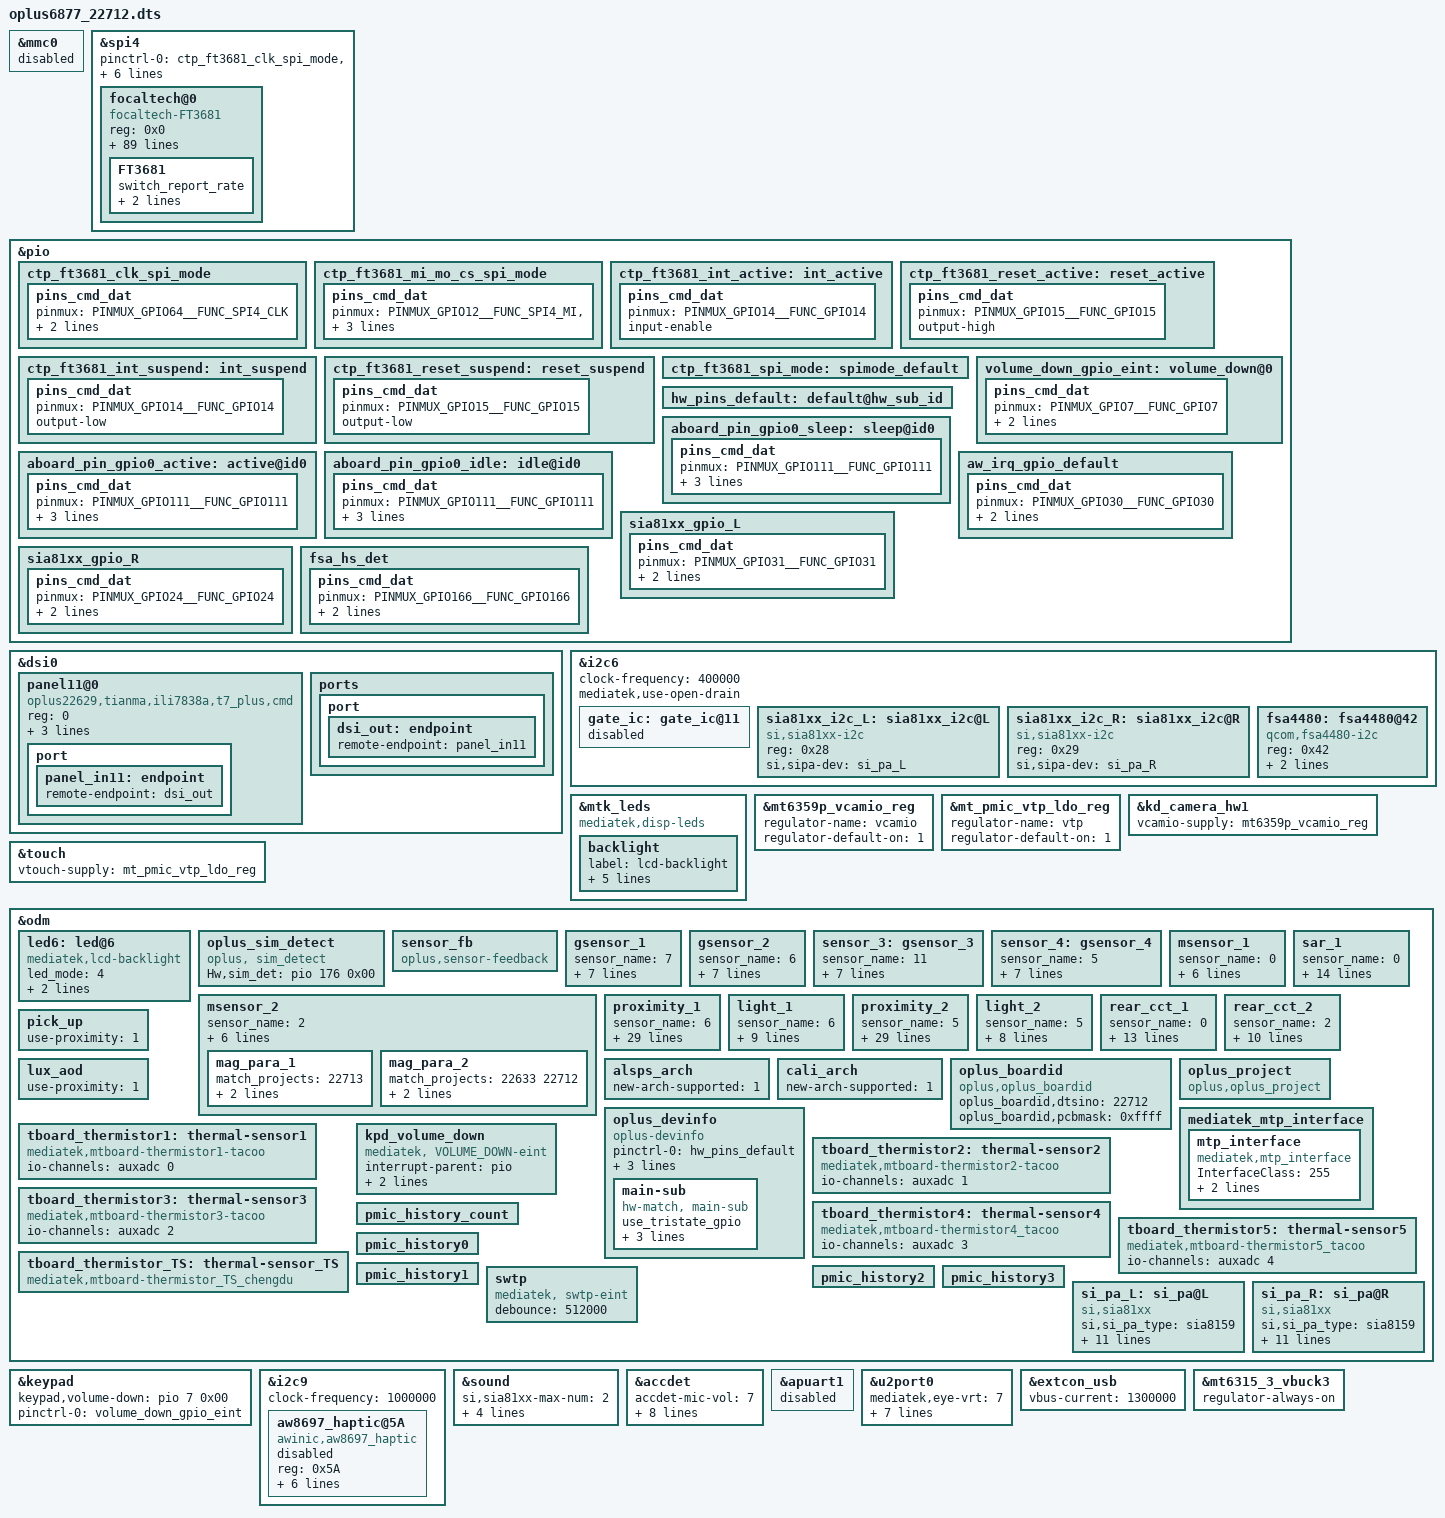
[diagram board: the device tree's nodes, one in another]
/*
 * Mediatek's mt6853 SoC device tree source
 *
 * Copyright (C) 2016 MediaTek Inc.
 *
 * This program is free software; you can redistribute it and/or modify
 * it under the terms of the GNU General Public License version 2 as
 * published by the Free Software Foundation.
 *
 * This program is distributed in the hope that it will be useful,
 * but WITHOUT ANY WARRANTY; without even the implied warranty of
 * MERCHANTABILITY or FITNESS FOR A PARTICULAR PURPOSE.
 * See http://www.gnu.org/licenses/gpl-2.0.html for more details.
 */
/dts-v1/;
/plugin/;
#include "k6877v1_64.dts"
#include "mediatek/nfc/mt6877_chengduB_nfc.dtsi"
/* #ifdef CONFIG_UFF_FINGERPRINT */
#include "mediatek/oplus_uff_22633_22712_22713.dtsi"
/* #endif CONFIG_UFF_FINGERPRINT */

&mmc0 {
        status = "disabled";
};

&spi4 {
	status = "okay";
	#address-cells = <1>;
	#size-cells = <0>;

	pinctrl-names = "default",  "ft3681_int_active",
		"ft3681_reset_active", "ft3681_int_suspend",
		"ft3681_reset_suspend", "ft3681_spi_mode";
	pinctrl-0 = <&ctp_ft3681_clk_spi_mode>, <&ctp_ft3681_mi_mo_cs_spi_mode>;
	pinctrl-1 = <&ctp_ft3681_int_active>;
	pinctrl-2 = <&ctp_ft3681_reset_active>;
	pinctrl-3 = <&ctp_ft3681_int_suspend>;
	pinctrl-4 = <&ctp_ft3681_reset_suspend>;
	pinctrl-5 = <&ctp_ft3681_spi_mode>;

	focaltech@0{
		compatible = "focaltech-FT3681";
		reg = <0x0>;
		chip-name = "FT3681";
		status = "okay";
		spi-max-frequency = <6000000>;
		/* Interrupt && Irq-gpio */
		interrupt-parent = <&pio>;
		interrupts = <14 0x2002>;

		/* Power Config */

		vdd_2v8-supply  = <&mt_pmic_vtp_ldo_reg>;
		vdd_2v8_volt = <3000000>;
		vcc_1v8-supply  = <&mt_pmic_vfp_ldo_reg>;
		vcc_1v8_volt = <1800000>;


		/* Other HW Resource */

		irq-gpio = <&pio 14 0x2002>;
		reset-gpio = <&pio 15 0x1>;

		touchpanel,max-num-support = <10>;
		touchpanel,tx-rx-num = <16 36>;
		earsense,tx-rx-num = <17 18>;
		touchpanel,panel-coords = <17280 38592>;
		touchpanel,display-coords = <1080 2412>;
		touchpanel,touchmajor-limit = <128 216>;
		touchpanel,elimination-range = <20 200 200>;
		//touchpanel,int-mode = <1>; /*0: interrupt and disable, 1:interrupt and not disable*/
		touchpanel,msecs-to-jiffies-time = <150>;
		touchpanel,smooth-level = <0 110 115 120 140 155>;
		touchpanel,smooth-level-charging = <0 110 115 120 140 155>;
		touchpanel,sensitive-level = <0 19 16 14 13 10>;
		touchpanel,tp-index = <0>;
		touchpanel,high-frame-rate-time = <20>;

		vid_len = <2>;
		firmware_name = "0xAB30500";
		tp_type = <7>; /* panel-TIANMA*/
                panel_type = <7>; /* panel-TIANMA*/
		platform_support_project = <22633 22712 22713>;
		platform_support_project_dir = <22633 22633 22633>;
		platform_support_project_commandline = "default_commandline","default_commandline","default_commandline";

		prevention,curved_screen_V2;
		prevention,grip_disable_level = <6>;
		prevention,updelay_time_ms = <30>;
		prevention,makeup_cnt_weight = <4 1 2 2 2>;
		prevention,large_corner_range = <1920 4800>;
		prevention,large_corner_judge_condition = <500 300 1600 6 6>;
		prevention,trx_reject_condition = <8 7 7>;
		prevention,trx_strict_reject_condition = <7 6 6>;
		prevention,large_judge_time_ms = <500 50 30>;
		prevention,large_exit_condition = <15 12 2>;
		prevention,single_channel_width = <512 512>;
		prevention,normal_tap_condition = <10 300>;
		prevention,long_edge_condition = <230 100 180 80>;
		prevention,long_strict_edge_condition = <170 80>;
		prevention,long_fingerhold_condition = <50 6 4 4>;
		prevention,short_edge_condition = <230 100 180 80>;
		prevention,short_strict_edge_condition = <160 60>;
		prevention,large_strict_exit_condition = <5 5>;
		prevention,top_corner_config = <800 2400 760>;
		prevention,edge_swipe_config = <480 1600>;

		prevention,curved_screen_V4;
		prevention,long_fingerhold_condition2 = <1120 3200 0 0>;
		prevention,top_corner_config2 =<3 80 420 2400 0>;
		prevention,hor_long_top_corner_config =<480 3200 0 0>;
		prevention,top_middle_config =<17280 1600 1600 0>;

		/* SW Support Feature Control */
		esd_handle_support;
		//register-is-16bit;
		//wireless_charger_support;
		headset_pump_support;
		//fw_edge_limit_support;

		health_monitor_support;
		black_gesture_support;
		charger_pump_support;
		//lcd_tp_refresh_support;
		fw_update_app_support;
		smart_gesture_support;
		game_switch_support;
		report_flow_unlock_support;
		kernel_grip_support;
		fingerprint_underscreen_support;
		pressure_report_support;
		touchpanel,single-optimized-time = <8>;
		auto_test_force_pass_support;
		snr_read_support;
		high_resolution_support_x16;
		algorithm_support;
		screenoff_fingerprint_info_support;
		irq_need_dev_resume_ok;
		sportify_aod_gesture_support;
		black_gesture_indep_support;
		thermal_detect_support;
		exception_upload_support;

		/*
		 *Virtual Key Config:
		 *1:touchpanel,button-type: <virtualkey_type  supportted_button-map>
		 *virtualkey_type:
		 *Type 1: using board_properties
		 *Type 2: using same IC (button zone&& touch zone are seprate)
		 *Type 3: using diffrent IC (button zone&& touch zone are seprate)
		 *Type 4: No need of virtual key process
		 *supportted_button-map:select|menu|home|back
		 *
		 *2:touchpanel,button-map
		 *type (X1,Y1)(X2,Y2)(X3,Y3)(Width_X,Hight_Y)--Only when button-type is 0
		 */
		touchpanel,button-type = <4>;
		touchpanel.button-TRx = <0 0>;

		FT3681 {
			switch_report_rate;
			report_rate_default = <60>;
			report_rate_game_value = <0x02>;
		};
	};
};

&pio {
	ctp_ft3681_clk_spi_mode: ctp_ft3681_clk_spi_mode{
		pins_cmd_dat {
			pinmux = <PINMUX_GPIO64__FUNC_SPI4_CLK>;
			mediatek,drive-strength-adv = <0>;/*EH[2:0]*/
			drive-strength = <2>;
		};
	};
	ctp_ft3681_mi_mo_cs_spi_mode: ctp_ft3681_mi_mo_cs_spi_mode {
		pins_cmd_dat {
			pinmux = <PINMUX_GPIO12__FUNC_SPI4_MI>,
				<PINMUX_GPIO13__FUNC_SPI4_MO>,
				<PINMUX_GPIO65__FUNC_SPI4_CSB>;
			drive-strength = <2>;
		};
	};
	ctp_ft3681_int_active: int_active {
		pins_cmd_dat {
			pinmux = <PINMUX_GPIO14__FUNC_GPIO14>;
			input-enable;
		};
	};
	ctp_ft3681_reset_active: reset_active {
		pins_cmd_dat {
			pinmux = <PINMUX_GPIO15__FUNC_GPIO15>;
			output-high;
		};
	};
	ctp_ft3681_int_suspend: int_suspend {
		pins_cmd_dat {
			pinmux = <PINMUX_GPIO14__FUNC_GPIO14>;
			output-low;
		};
	};
	ctp_ft3681_reset_suspend: reset_suspend {
		pins_cmd_dat {
			pinmux = <PINMUX_GPIO15__FUNC_GPIO15>;
			output-low;
		};
	};
	ctp_ft3681_spi_mode: spimode_default {
	};
};
/*touch end*/

&dsi0 {
	status = "okay";
	#address-cells = <1>;
	#size-cells = <0>;
	panel11@0 {
		compatible = "oplus22629,tianma,ili7838a,t7_plus,cmd";
		reg = <0>;
		vddr-enable-gpios = <&pio 107 0>;
		reset-gpios = <&pio 40 0>;
		ldo3-supply = <&mt_pmic_vmc_ldo_reg>;
		pinctrl-names = "default";
		port {
			panel_in11: endpoint {
				remote-endpoint = <&dsi_out>;
			};
		};
	};
	ports {
		port {
			dsi_out: endpoint {
				remote-endpoint = <&panel_in11>;
			};
		};
	};
};

&i2c6 {
	gate_ic: gate_ic@11 {
		status = "disable";
	};
};

&mtk_leds {
	compatible = "mediatek,disp-leds";
	backlight {
		label = "lcd-backlight";
		max-brightness = <20479>;
		led-bits = <14>;
		trans-bits = <14>;
		support_silky_brightness = <1>;
		default-state = "on";
	};
};
&mt6359p_vcamio_reg {
	regulator-name = "vcamio";
	regulator-default-on = <1>; /* 0:skip, 1: off, 2:on */
	status = "okay";
};
&mt_pmic_vtp_ldo_reg {
	regulator-name = "vtp";
	regulator-default-on = <1>; /* 0:skip, 1: off, 2:on */
	status = "okay";
};

&kd_camera_hw1 {
	vcamio-supply = <&mt6359p_vcamio_reg>;
	status = "okay";
};

&touch {
	vtouch-supply = <&mt_pmic_vtp_ldo_reg>;
	status = "okay";
};


&odm {
	led6:led@6 {
		compatible = "mediatek,lcd-backlight";
		led_mode = <4>;
		data = <1>;
		pwm_config = <0 1 0 0 0>;
	};
    oplus_sim_detect {
	    compatible = "oplus, sim_detect";
	    Hw,sim_det = <&pio 176 0x00>;
    };
/* sensor start */
	/*
	enum {
		LIS3DH,
		LSM6DS3,
		BMI160,
		LIS2HH12,
		LSM6DSM,
		BMI2XY,
		LSM6DSO,
		BMA4XY,
		SC7A20,
		ICM4X6XX,
	};
	*/
    sensor_fb: sensor_fb {
            compatible = "oplus,sensor-feedback";
    };

	gsensor_1: gsensor_1 {
		status = "okay";
		sensor_name = <7>;//ICM4X6XX
		i2c_num = <2>;
		i2c_addr = <0>;
		direction = <1>;
		eint_num = <1>;
		step_count_7_en = <1>;
		config_miso = <1>;
		correct_y_bias = <1>;
	};
	gsensor_2: gsensor_2 {
		status = "okay";
		sensor_name = <6>;//LSM6DSO
		device_name = "lsm6dso";
		i2c_num = <2>;
		i2c_addr = <0>;
		direction = <5>;
		eint_num = <20>;
		gyro_cali_version= <2>; //should be always v2 for lsm6dso
		acc_cali_range= <200 200 200>;
	};
	sensor_3: gsensor_3 {
		status = "okay";
		sensor_name = <11>;//ICM42607
		device_name = "icm4n607";
		i2c_num = <2>;
		i2c_addr = <0>;
		direction = <1>;
		eint_num = <1>;
		gyro_cali_version= <2>;
		acc_cali_range= <300 300 300>; //300mg
	};
	sensor_4: gsensor_4 {
		status = "okay";
		sensor_name = <5>;//BMI2XY
		device_name = "bmi2xy";
		i2c_num = <2>;
		i2c_addr = <0>;
		direction = <7>;
		eint_num = <1>;
		gyro_cali_version= <2>;
		acc_cali_range= <300 300 300>; //250mg
	};
	/*
	enum {
		AKM09911,
		MMC3530,
		MMC5603,
		MXG4300,
	};
	*/
	msensor_1: msensor_1 {
		status = "okay";
		sensor_name = <0>;//AKM09911
		i2c_num = <0>;
		i2c_addr = <12>;
		direction = <6>;
		eint_num = <0>;
		soft-mag-parameter = <11497 0 261 1 3 1 123 1 9270 0 267 0 217 0 155 0 11455 0>;
	};
	msensor_2: msensor_2 {
		status = "okay";
		sensor_name = <2>;//MMC5603
		i2c_num = <0>;
		i2c_addr = <48>;
		direction = <3>;
		eint_num = <0>;
		para_num = <2>;
		libname = "mmc";
		mag_para_1 {
			match_projects = <22713>;
			soft-mag-parameter = <9987 0 336 0 362 1 108 1 8583 0 178 0 264 1 94 0 10321 0>;
		};
		mag_para_2 {
			match_projects = <22633 22712>;
			soft-mag-parameter = <9994 0 247 0 243 1 238 0 9424 0 42 0 17 0 139 1 10302 0>;
		};
	};
	/*
	enum {
		SX933x
	};
	*/
	sar_1: sar_1 {
		status = "okay";
		sensor_name = <0>;//SX933x
		i2c_num = <0>;
		i2c_addr = <40>;
		direction = <4>;
		eint_num = <13>;
		channel_num = <2>;
		channel_0_min = <0>;
		channel_0_max = <70000>;
		channel_1_min = <0>;
		channel_1_max = <70000>;
		channel_2_min = <0>;
		channel_2_max = <70000>;
		channel_3_min = <0>;
		channel_3_max = <70000>;
		reg_table_num = <3>;
	};
	/*
	enum {
		TMD2725,
		APSD9922,
		STK3335,
		STK3331,
		STK2232,
		TCS3701,
		STK32600,
	};
	*/
	proximity_1: proximity_1 {
		status = "okay";
		sensor_name = <6>;//STK32600
		i2c_num = <0>;
		i2c_addr = <72>;
		direction = <4>;
		eint_num = <2>;
		low_step = <300>;
		high_step = <400>;
		low_limit = <400>;
		high_limit = <600>;
		dirty_low_step = <300>;
		dirty_high_step = <400>;
		ps_dirty_limit = <1800>;
		ps_ir_limit = <2000>;
		ps_adjust_min = <0>;
		ps_adjust_max = <1850>;
		sampling_count = <5>;
		step_max = <400>;
		step_min = <100>;
		step_div = <2000>;
		anti_shake_delta = <70>;
		dynamic_cali_max = <5000>;
		raw2offset_radio = <1000>;
		offset_max = <60000>;
		offset_range_min = <0>;
		offset_range_max = <65535>;
		force_cali_limit = <2000>;
		cali_jitter_limit = <30>;
		cal_offset_margin = <3000>;
		sensor-reg = <0x03 0x28>;
		is_use_force_cali = <1>;
	};
	light_1: light_1 {
		status = "okay";
		sensor_name = <6>;//STK32600
		i2c_num = <0>;
		i2c_addr = <72>;
		direction = <4>;
		eint_num = <2>;
		als_buffer_length =<8>;
		als_ratio = <110>;
		als_type = <2>;//<1-normal;2-under screen;3-normal needed compensation>
		device_name = "stk32600";
		use_als_c2 = <1>;
	};
	proximity_2: proximity_2 {
		status = "okay";
		sensor_name = <5>;//TCS3701
		i2c_num = <0>;
		i2c_addr = <57>;
		direction = <4>;
		eint_num = <2>;
		low_step = <300>;
		high_step = <400>;
		low_limit = <400>;
		high_limit = <600>;
		dirty_low_step = <180>;
		dirty_high_step = <250>;
		ps_dirty_limit = <1020>;
		ps_ir_limit = <500>;
		ps_adjust_min = <0>;
		ps_adjust_max = <600>;
		sampling_count = <5>;
		step_max = <400>;
		step_min = <110>;
		step_div = <1500>;
		anti_shake_delta = <80>;
		dynamic_cali_max = <1024>;
		raw2offset_radio = <31200>;
		offset_max = <250>;
		offset_range_min = <255>;
		offset_range_max = <255>;
		force_cali_limit = <2000>;
		cali_jitter_limit = <30>;
		cal_offset_margin = <120>;
		sensor-reg = <0xBC 0xFB 0xB9 0x1C>;
		is_use_force_cali = <1>;
	};
	light_2: light_2 {
		status = "okay";
		sensor_name = <5>;//TCS3701
		i2c_num = <0>;
		i2c_addr = <57>;
		direction = <4>;
		eint_num = <2>;
		als_ratio = <110>;
		als_buffer_length = <10>;
		als_type = <2>;
		device_name = "tcs3701";
	};
	/*
	enum {
		STK37600,
		MN29005,
		TCS3408,
	};
	*/
	rear_cct_1: rear_cct_1 {
		status = "okay";
		sensor_name = <0>;//STK37600
		i2c_num = <1>;
		i2c_addr = <0x48>;
		direction = <0>;
		eint_num = <10>;
		available_sensor = <7>; // bit 0: rear als, bit 1: rear cct, bit 2: rear flicker
		gold_rear_cct_3k = <11083 14060 1700 488 64 42136>; // 3000k gold parameter
		gold_rear_cct_6k = <8488 13068 3928 372 64 42964>;  // 3000k gold parameter
		device_name = "stk37600";
		cct_coef_Lir = <9116000 0 259000 0 1711000 1 7351000 0 12875000 0
				1686000 0 3545000 0 6606000 0 51505000 0 3221000 1
				2492000 1 2826000 1>;
		cct_coef_Hir = <178000 1 14775000 1 36798000 1 13552000 0 24758000 0
				31340000 0 3274000 1 7368000 1 19817000 0 161000 1
				23000 0 392000 0>;
	};
	rear_cct_2: rear_cct_2 {
		status = "okay";
		sensor_name = <2>;//TCS3408
		i2c_num = <1>;
		i2c_addr = <0x39>;
		direction = <0>;
		eint_num = <10>;
		available_sensor = <7>; // bit 0: rear als, bit 1: rear cct, bit 2: rear flicker
		gold_rear_cct_3k = <5140 2597 1342 8413 3080 2101>; // 3000k gold parameter
		gold_rear_cct_6k = <3465 2885 2046 7898 2864 3986>;  // 3000k gold parameter
		device_name = "tcs3408";
	};
	pick_up: pick_up {
		status = "okay";
		use-proximity = <1>;
	};
	lux_aod: lux_aod {
		status = "okay";
		use-proximity = <1>;
	};
	alsps_arch: alsps_arch {
		status = "okay";
		new-arch-supported = <1>;
	};
	cali_arch: cali_arch {
		status = "okay";
		new-arch-supported = <1>;
	};
/* sensor end */

	oplus_boardid:oplus_boardid {
		compatible = "oplus,oplus_boardid";
		oplus_boardid,dtsino="22712";//only one u32
		oplus_boardid,pcbmask="0xffff";//all mask 0xffff
	};

/* OPLUS_BUG_STABILITY oppo project start */
	oplus_project:oplus_project {
		compatible = "oplus,oplus_project";
	};
	oplus_devinfo:oplus_devinfo {
		compatible = "oplus-devinfo";

		pinctrl-names = "default", "aboard_gpio0_sleep", "aboard_gpio0_active", "aboard_gpio0_idle";
		pinctrl-0 = <&hw_pins_default>;
		pinctrl-1 = <&aboard_pin_gpio0_sleep>;
		pinctrl-2 = <&aboard_pin_gpio0_active>;
		pinctrl-3 = <&aboard_pin_gpio0_idle>;
		main-sub {
			use_tristate_gpio;
            compatible = "hw-match, main-sub";
			aboard-gpio0 = <&pio 111 0x00>;
			aboard-patterns = <0 0 0>;
			/*main board*/
			match-projects = <22633 22712 22713>;
        };
	};
/* OPLUS_BUG_STABILITY oppo project end */

	mediatek_mtp_interface:mediatek_mtp_interface {
		mtp_interface {
			compatible = "mediatek,mtp_interface";
			InterfaceClass = <255>;
			InterfaceSubClass = <255>;
			InterfaceProtocol = <0>;
	};
};


/*
	tboard_thermistor5: thermal-sensor5 {
		compatible = "mediatek,mtboard-thermistor5";
		io-channels = <&auxadc 4>;
		io-channel-names = "thermistor-ch4";
	};
*/
	/* 20230109, add for AP, 4G pA, 5G PA, charger, sub_bat, flashlight ntc*/
	tboard_thermistor1: thermal-sensor1 {
		compatible = "mediatek,mtboard-thermistor1-tacoo";
		io-channels = <&auxadc 0>;
		io-channel-names = "thermistor-ch0";
	};
	tboard_thermistor2: thermal-sensor2 {
		compatible = "mediatek,mtboard-thermistor2-tacoo";
		io-channels = <&auxadc 1>;
		io-channel-names = "thermistor-ch1";
	};
	tboard_thermistor3: thermal-sensor3 {
		compatible = "mediatek,mtboard-thermistor3-tacoo";
		io-channels = <&auxadc 2>;
		io-channel-names = "thermistor-ch2";
	};
	tboard_thermistor4: thermal-sensor4 {
		compatible = "mediatek,mtboard-thermistor4_tacoo";
		io-channels = <&auxadc 3>;
		io-channel-names = "thermistor-ch3";
	};
	tboard_thermistor5: thermal-sensor5 {
		compatible = "mediatek,mtboard-thermistor5_tacoo";
		io-channels = <&auxadc 4>;
		io-channel-names = "thermistor-ch4";
	};
	tboard_thermistor_TS: thermal-sensor_TS {
		compatible = "mediatek,mtboard-thermistor_TS_chengdu";
	};

	kpd_volume_down:kpd_volume_down {
		compatible = "mediatek, VOLUME_DOWN-eint";
		interrupt-parent = <&pio>;
		interrupts = <7 IRQ_TYPE_EDGE_FALLING 7 0>;
		debounce = <32000>;
		status = "okay";
	};

	pmic_history_count:pmic_history_count {
	};
	pmic_history0:pmic_history0 {
	};
	pmic_history1:pmic_history1 {
	};
	pmic_history2:pmic_history2 {
	};
	pmic_history3:pmic_history3 {
	};
	//#ifdef OPLUS_VENDOR_SWTP
	swtp: swtp {
		compatible = "mediatek, swtp-eint";
		debounce = <512000>;
	};
	//#endif  /*OPLUS_VENDOR_SWTP*/

};

&keypad {
	keypad,volume-down	= <&pio 7 0x00>;
	pinctrl-names = "volume_down_as_int";
	pinctrl-0 = <&volume_down_gpio_eint>;
	status = "okay";
};

&pio {
	volume_down_gpio_eint:volume_down@0{
		pins_cmd_dat {
			pinmux = <PINMUX_GPIO7__FUNC_GPIO7>;
			slew-rate = <0>;  /*direction 0:in, 1:out*/
			input-enable;
		};
	};
};

&pio {
        hw_pins_default:default@hw_sub_id {
        };

        aboard_pin_gpio0_sleep:sleep@id0 {
                pins_cmd_dat {
                        pinmux = <PINMUX_GPIO111__FUNC_GPIO111>;
                        slew-rate = <0>;
                        bias-pull-down;
                        input-enable;
                };
        };

        aboard_pin_gpio0_active:active@id0 {
                pins_cmd_dat {
                        pinmux = <PINMUX_GPIO111__FUNC_GPIO111>;
                        slew-rate = <0>;
                        bias-pull-up;
                        input-enable;
                };
        };

        aboard_pin_gpio0_idle:idle@id0 {
                pins_cmd_dat {
                        pinmux = <PINMUX_GPIO111__FUNC_GPIO111>;
                        slew-rate = <0>;
                        bias-disable;
                        input-enable;
                };
        };
};

&i2c9 {
    status = "okay";
	clock-frequency = <1000000>;

	/* AWINIC AW8697 Haptic */
	aw8697_haptic@5A {
		status = "disabled";
		compatible = "awinic,aw8697_haptic";
		reg = <0x5A>;
		reset-gpio = <&pio 26 0x00>;
		irq-gpio = <&pio 30 0x00>;
		qcom,device_id = <815>;//aw86927
		audio_delay = <60>;
		qcom,aw86927_boost_voltage = /bits/ 8 <0x5E>;

		pinctrl-names = "default";
		pinctrl-0 = <&aw_irq_gpio_default>;
	};
};

&pio{
	aw_irq_gpio_default: aw_irq_gpio_default {		//check
		pins_cmd_dat {
			pinmux = <PINMUX_GPIO30__FUNC_GPIO30>;
			input-enable;
			bias-pull-down = <MTK_PUPD_SET_R1R0_10>;
		};
	};

};

&pio {
	sia81xx_gpio_L: sia81xx_gpio_L {
		pins_cmd_dat {
			pinmux = <PINMUX_GPIO31__FUNC_GPIO31>;
			slew-rate = <1>;
			bias-disable;
		};
	};

	sia81xx_gpio_R: sia81xx_gpio_R {
		pins_cmd_dat {
			pinmux = <PINMUX_GPIO24__FUNC_GPIO24>;
			slew-rate = <1>;
			bias-disable;
		};
	};
};

&odm {
	si_pa_L: si_pa@L {
		compatible = "si,sia81xx";
		si,si_pa_type = "sia8159";
		si,si_pa_reset = <&pio 31 0>;
		si,si_pa_owi = <&pio 31 0>;
		pinctrl-names = "sia81xx_gpio";
		pinctrl-0 = <&sia81xx_gpio_L>;
		si,si_pa_disable_pin = <1>;
		/* the same value share a same task
		* valid value range : 0 ~ 7 */
		timer_task_hdl = <0>;
		channel_num = <0>;
		owi_mode = <6>;
		en_x_filter = <0>;
		en_dynamic_updata_vdd = <0>;
		en_dynamic_updata_pvdd = <0>;
		dynamic_updata_vdd_port = <0x2>;
	};
	si_pa_R: si_pa@R {
		compatible = "si,sia81xx";
		si,si_pa_type = "sia8159";
		si,si_pa_reset = <&pio 24 0>;
		si,si_pa_owi = <&pio 24 0>;
		pinctrl-names = "sia81xx_gpio";
		pinctrl-0 = <&sia81xx_gpio_R>;
		si,si_pa_disable_pin = <1>;
		/* the same value share a same task
		* valid value range : 0 ~ 7 */
		timer_task_hdl = <0>;
		channel_num = <1>;
		owi_mode = <6>;
		en_x_filter = <0>;
		en_dynamic_updata_vdd = <0>;
		en_dynamic_updata_pvdd = <0>;
		dynamic_updata_vdd_port = <0x2>;
	};
};


&sound {
	si,sia81xx-max-num = <2>;
	si,sia81xx-aux-devs = <&si_pa_L>, <&si_pa_R>;
	si,sia81xx-aux-devs-prefix = "SpkrLeft", "SpkrRight";
	si,is_analog_pa = <1>;
};

//#ifdef OPLUS_TFA98XX
&i2c6 {
	#address-cells = <1>;
	#size-cells = <0>;
	clock-frequency = <400000>;
	mediatek,use-open-drain;

	sia81xx_i2c_L: sia81xx_i2c@L {
		compatible = "si,sia81xx-i2c";
		reg = <0x28>;
		si,sipa-dev = <&si_pa_L>;
	};

	sia81xx_i2c_R: sia81xx_i2c@R {
		compatible = "si,sia81xx-i2c";
		reg = <0x29>;
		si,sipa-dev = <&si_pa_R>;
	};
};

&accdet {
	/* accdet micbias voltage: 0x09:2.85v 0x08:2.8v 0x07,
	 * 2.7v;0x05,2.5v;0x02,1.9v
	 */
	accdet-mic-vol = <7>;
	/* accdet pwm_width, pwm_thresh, fall_delay, rise_delay
	 * debounce0, debounce1, debounce3, debounce4
	 * eint pwm_width, eint pwm_thresh
	 * eint deb(debounce0, debounce1, debounce2, debounce3), inv_debounce
	 */
	headset-mode-setting = <0x500 0x500 1 0x1f0
				0x800 0x800 0x20 0x44
				0x4 0x1
				0x5 0x3 0x3 0x5 0xe>;
	accdet-plugout-debounce = <1>;
	/*1:ACC mode, 2:low cost without in bias, 6:low cost with in bias*/
	accdet-mic-mode = <2>;
	/*0--MD_MAX--UP_MAX--DW_MAX*/
	headset-three-key-threshold = <0 82 170 306>;
	//#else
	//headset-three-key-threshold = <0 80 220 400>;
	//#endif
	headset-three-key-threshold-CDD = <0 121 192 600>;
	/*0--MD_MAX--VOICE_MAX--UP_MAX--DW_MAX*/
	headset-four-key-threshold = <0 58 121 192 400>;

	/* select VTH to 2v and 500k, use internal resitance */
	eint_use_ext_res = <0>;
	status = "okay";
};

&pio {
	fsa_hs_det: fsa_hs_det {
		pins_cmd_dat {
			pinmux = <PINMUX_GPIO166__FUNC_GPIO166>;
			slew-rate = <1>;  /*direction 0:in, 1:out*/
			output-high;
		};
	};
};

&i2c6 {
	fsa4480: fsa4480@42 {
		compatible = "qcom,fsa4480-i2c";
		reg = <0x42>;
		pinctrl-names = "default";
		pinctrl-0 = <&fsa_hs_det>;
		fsa4480,hs-det-gpio = <&pio 166 0>;
	};
};

&apuart1 {
	status = "disabled";
};


&u2port0 {
	mediatek,eye-vrt = <7>; /* 0~7 */
	mediatek,eye-term = <5>; /* 0~7 */
	mediatek,rev6 = <3>; /* 0~3 */
	mediatek,discth = <7>; /* 0~8 */
	mediatek,eye-vrt-host = <6>; /* 0~7 */
	mediatek,eye-term-host = <3>; /* 0~7 */
	mediatek,rev6-host = <3>; /* 0~3 */
	mediatek,disc-host = <0xf>; /* 0~8 */
};
&extcon_usb {
	vbus-current = <1300000>;
};

&mt6315_3_vbuck3 {
	regulator-always-on;
};

//#endif  /*OPLUS_VENDOR_SWTP*/
#include <oplus6877_22712/cust.dtsi>
#include "mediatek/cust_mt6877_22633_charge.dtsi"
/*#include "mediatek/cust_mt6877_touch_1080x2300.dtsi"*/
#include "mediatek/cust_mt6877_camera_22633.dtsi"
/*End of this file, DO NOT ADD ANYTHING HERE*/

